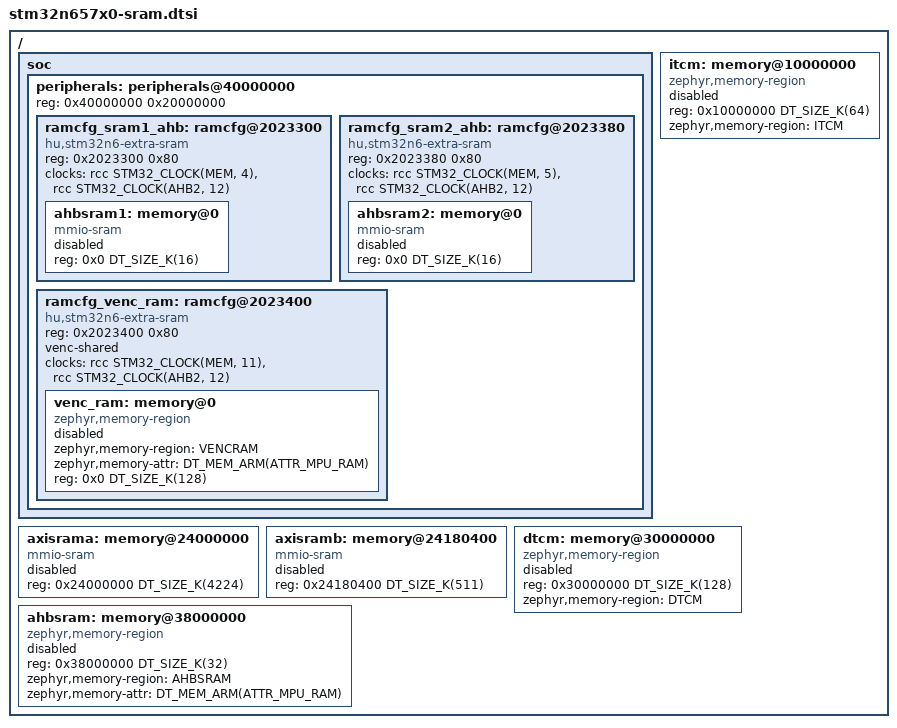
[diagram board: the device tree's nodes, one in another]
/*
 * Copyright (c) 2025 HU Inc. All rights reserved.
 *
 * SPDX-License-Identifier: Apache-2.0
 */

#include <arm/armv8.1-m.dtsi>
#include <zephyr/dt-bindings/clock/stm32n6_clock.h>
#include <zephyr/dt-bindings/reset/stm32n6_reset.h>
#include <zephyr/dt-bindings/memory-attr/memory-attr.h>
#include <zephyr/dt-bindings/memory-attr/memory-attr-arm.h>
#include <freq.h>

/ {
	soc {
		#address-cells = <1>;
		#size-cells = <1>;

		peripherals: peripherals@40000000 {
			#address-cells = <1>;
			#size-cells = <1>;
			reg = <0x40000000 0x20000000>;
			/* Default use the secure addresses range */
			ranges = <0x0 0x50000000 0x10000000>;
			ramcfg_sram1_ahb: ramcfg@2023300 {
				compatible = "hu,stm32n6-extra-sram";
				#address-cells = <1>;
				#size-cells = <1>;
				reg = <0x2023300 0x80>;
				clocks = <&rcc STM32_CLOCK(MEM, 4)>, <&rcc STM32_CLOCK(AHB2, 12)>;
				clock-names = "sram", "ramcfg";
				ranges = <0x0 0x38000000 DT_SIZE_K(16)>;

				ahbsram1: memory@0 {
					compatible = "mmio-sram";
					reg = <0x0 DT_SIZE_K(16)>;
					status = "disabled";
				};
			};
			ramcfg_sram2_ahb: ramcfg@2023380 {
				compatible = "hu,stm32n6-extra-sram";
				#address-cells = <1>;
				#size-cells = <1>;
				reg = <0x2023380 0x80>;
				clocks = <&rcc STM32_CLOCK(MEM, 5)>, <&rcc STM32_CLOCK(AHB2, 12)>;
				clock-names = "sram", "ramcfg";
				ranges = <0x0 0x38004000 DT_SIZE_K(16)>;

				ahbsram2: memory@0 {
					compatible = "mmio-sram";
					reg = <0x0 DT_SIZE_K(16)>;
					status = "disabled";
				};
			};
			ramcfg_venc_ram: ramcfg@2023400 {
				compatible = "hu,stm32n6-extra-sram";
				#address-cells = <1>;
				#size-cells = <1>;
				reg = <0x2023400 0x80>;
				venc-shared;
				clocks = <&rcc STM32_CLOCK(MEM, 11)>, <&rcc STM32_CLOCK(AHB2, 12)>;
				clock-names = "sram", "ramcfg";
				ranges = <0x0 0x34400000 DT_SIZE_K(128)>;

				venc_ram: memory@0 {
					compatible = "zephyr,memory-region", "mmio-sram";
					zephyr,memory-region = "VENCRAM";
					zephyr,memory-attr = <DT_MEM_ARM(ATTR_MPU_RAM)>;
					reg = <0x0 DT_SIZE_K(128)>;
					status = "disabled";
				};
			};
		};
	};

	axisrama: memory@24000000 {
		compatible = "mmio-sram";
		reg = <0x24000000 DT_SIZE_K(4224)>;
		status = "disabled";
	};

	axisramb: memory@24180400 {
		compatible = "mmio-sram";
		reg = <0x24180400 DT_SIZE_K(511)>;
		status = "disabled";
	};

	itcm: memory@10000000 {
		compatible = "zephyr,memory-region", "arm,itcm";
		reg = <0x10000000 DT_SIZE_K(64)>;
		zephyr,memory-region = "ITCM";
		status = "disabled";
	};

	dtcm: memory@30000000 {
		compatible = "zephyr,memory-region", "arm,dtcm";
		reg = <0x30000000 DT_SIZE_K(128)>;
		zephyr,memory-region = "DTCM";
		status = "disabled";
	};

	ahbsram: memory@38000000 {
		compatible = "zephyr,memory-region", "mmio-sram";
		reg = <0x38000000 DT_SIZE_K(32)>;
		zephyr,memory-region = "AHBSRAM";
		zephyr,memory-attr = <DT_MEM_ARM(ATTR_MPU_RAM)>;
		status = "disabled";
	};
};
